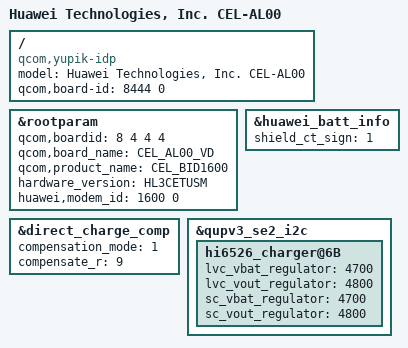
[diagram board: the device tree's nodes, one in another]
/dts-v1/;
/plugin/;

#include "../common/common-pm7250b.dtsi"
#include "huawei-nfc.dtsi"
#include "huawei_camera.dtsi"
#include "huawei_wifi.dtsi"
#include "huawei_dp.dtsi"
#include "huawei_charger.dtsi"
#include "huawei_bt.dtsi"
/ {
    /* bsp_replace_info @ model = "Huawei Technologies, Inc. %product_name%"; */
    model = "Huawei Technologies, Inc. CEL-AL00";
    compatible = "qcom,yupik-idp", "qcom,yupik", "qcom,idp";
    /* bsp_replace_info @ qcom,board-id = <%boardid% 0>; */
    qcom,board-id = <8444 0>;
};

&rootparam {
    /* bsp_replace_info @ qcom,boardid = <%boardid_split%>; */
    /* auto_key_info @ name: boardid type: uint32 default: 0 */
    qcom,boardid = <8 4 4 4>;
    /* bsp_replace_info @ qcom,board_name = "%board_name%"; */
    qcom,board_name = "CEL_AL00_VD";
    /* bsp_replace_info @ qcom,product_name = "%product_name%"; */
    qcom,product_name = "CEL_BID1600";
    /* bsp_replace_info @ hardware_version = "%hardware_version%"; */
    hardware_version = "HL3CETUSM";
    /* bsp_replace_info @ huawei,modem_id = <%modem_id% 0x0>; */
    huawei,modem_id = <1600 0>;
};

&huawei_batt_info {
	shield_ct_sign = <1>;
};

&direct_charge_comp {
	compensation_mode = <1>;
	compensate_r = <9>;
};

&qupv3_se2_i2c {
	hi6526_charger@6B {
		lvc_vbat_regulator = <4700>;
		lvc_vout_regulator = <4800>;
		sc_vbat_regulator = <4700>;
		sc_vout_regulator = <4800>;
	};
};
